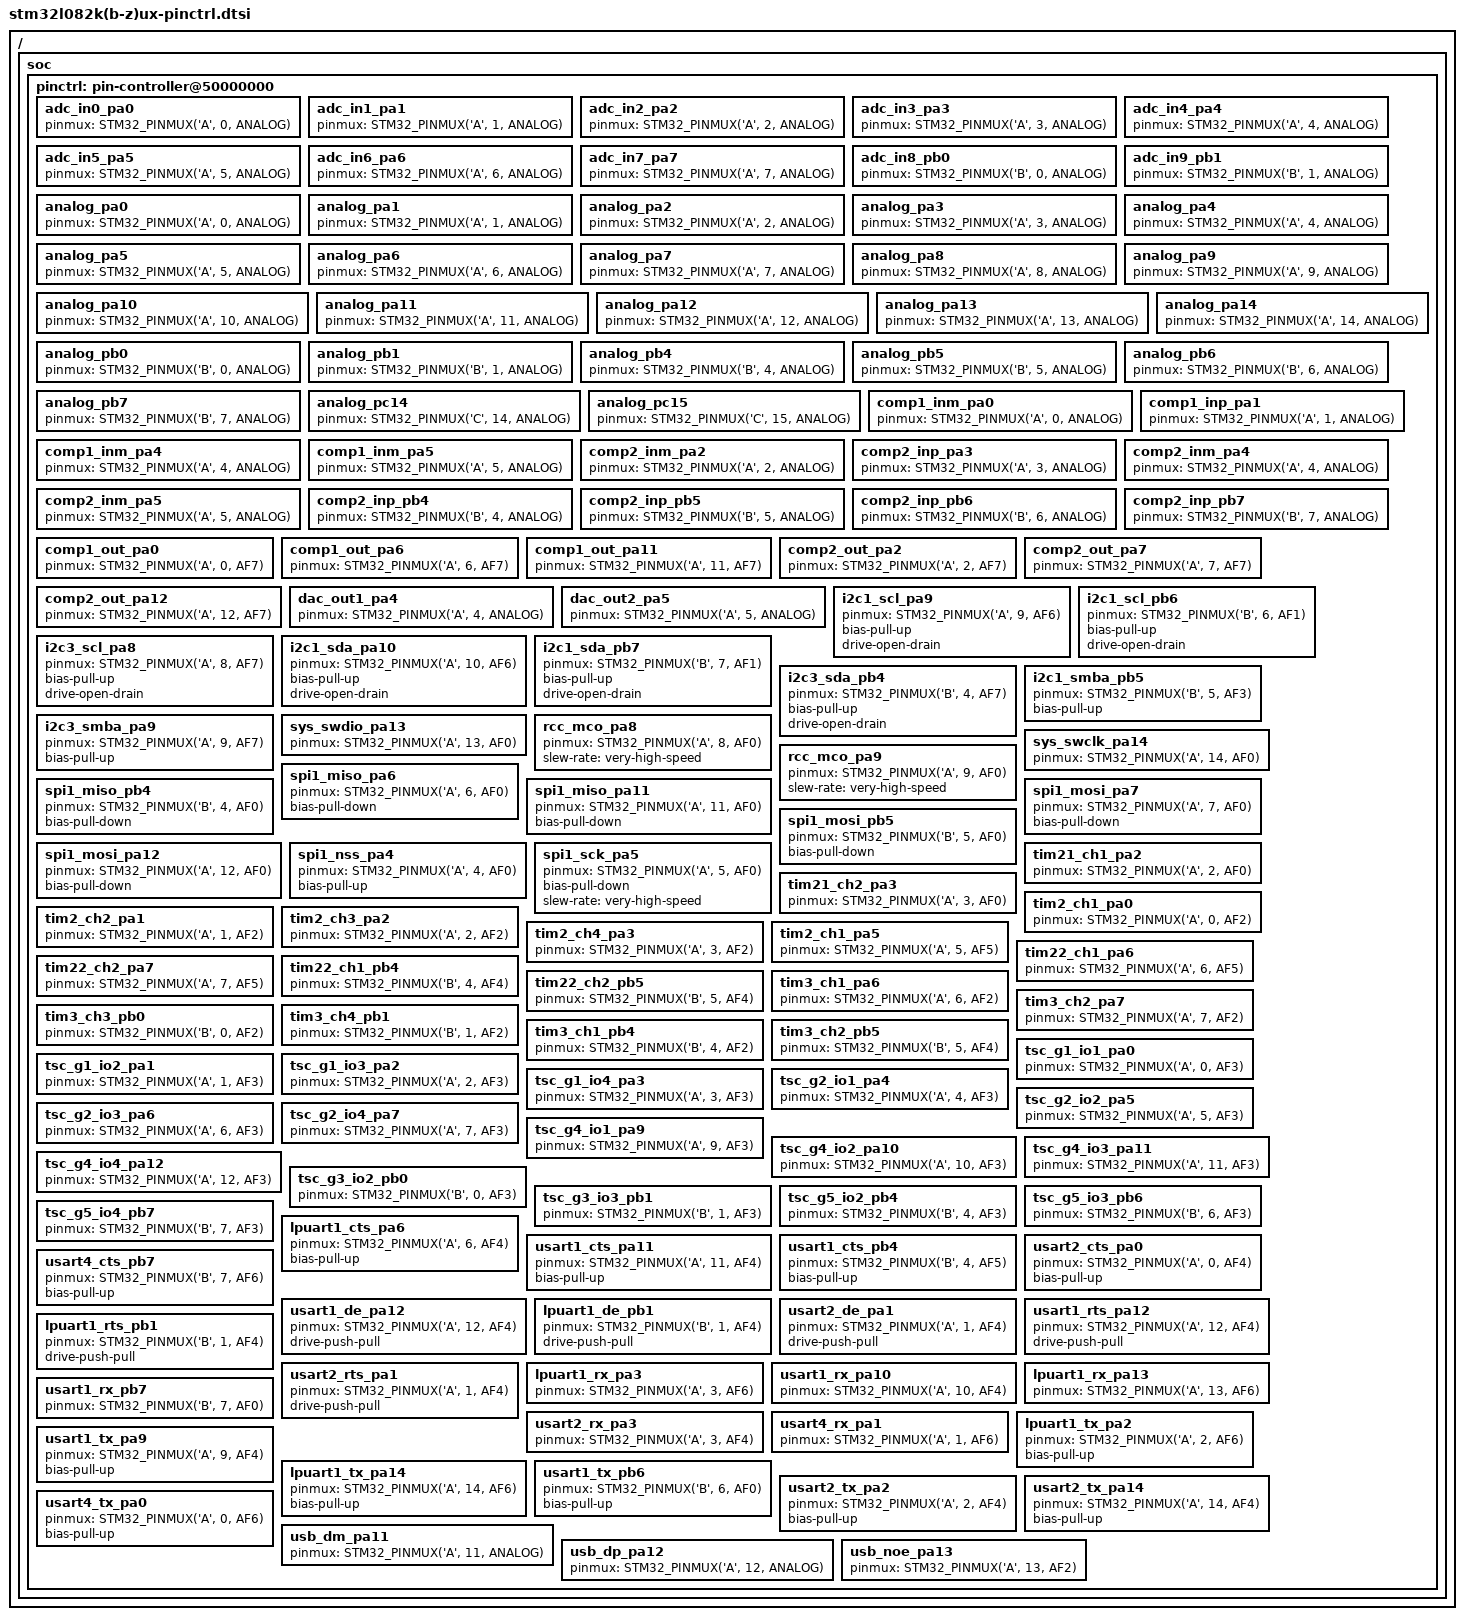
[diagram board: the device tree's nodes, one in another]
/*
 * NOTE: Autogenerated file using genpinctrl.py
 *
 * SPDX-License-Identifier: Apache-2.0
 */

#include <zephyr/dt-bindings/pinctrl/stm32-pinctrl.h>

/ {
	soc {
		pinctrl: pin-controller@50000000 {

			/* ADC_IN / ADC_INN / ADC_INP */

			/omit-if-no-ref/ adc_in0_pa0: adc_in0_pa0 {
				pinmux = <STM32_PINMUX('A', 0, ANALOG)>;
			};

			/omit-if-no-ref/ adc_in1_pa1: adc_in1_pa1 {
				pinmux = <STM32_PINMUX('A', 1, ANALOG)>;
			};

			/omit-if-no-ref/ adc_in2_pa2: adc_in2_pa2 {
				pinmux = <STM32_PINMUX('A', 2, ANALOG)>;
			};

			/omit-if-no-ref/ adc_in3_pa3: adc_in3_pa3 {
				pinmux = <STM32_PINMUX('A', 3, ANALOG)>;
			};

			/omit-if-no-ref/ adc_in4_pa4: adc_in4_pa4 {
				pinmux = <STM32_PINMUX('A', 4, ANALOG)>;
			};

			/omit-if-no-ref/ adc_in5_pa5: adc_in5_pa5 {
				pinmux = <STM32_PINMUX('A', 5, ANALOG)>;
			};

			/omit-if-no-ref/ adc_in6_pa6: adc_in6_pa6 {
				pinmux = <STM32_PINMUX('A', 6, ANALOG)>;
			};

			/omit-if-no-ref/ adc_in7_pa7: adc_in7_pa7 {
				pinmux = <STM32_PINMUX('A', 7, ANALOG)>;
			};

			/omit-if-no-ref/ adc_in8_pb0: adc_in8_pb0 {
				pinmux = <STM32_PINMUX('B', 0, ANALOG)>;
			};

			/omit-if-no-ref/ adc_in9_pb1: adc_in9_pb1 {
				pinmux = <STM32_PINMUX('B', 1, ANALOG)>;
			};

			/* Analog */

			/omit-if-no-ref/ analog_pa0: analog_pa0 {
				pinmux = <STM32_PINMUX('A', 0, ANALOG)>;
			};

			/omit-if-no-ref/ analog_pa1: analog_pa1 {
				pinmux = <STM32_PINMUX('A', 1, ANALOG)>;
			};

			/omit-if-no-ref/ analog_pa2: analog_pa2 {
				pinmux = <STM32_PINMUX('A', 2, ANALOG)>;
			};

			/omit-if-no-ref/ analog_pa3: analog_pa3 {
				pinmux = <STM32_PINMUX('A', 3, ANALOG)>;
			};

			/omit-if-no-ref/ analog_pa4: analog_pa4 {
				pinmux = <STM32_PINMUX('A', 4, ANALOG)>;
			};

			/omit-if-no-ref/ analog_pa5: analog_pa5 {
				pinmux = <STM32_PINMUX('A', 5, ANALOG)>;
			};

			/omit-if-no-ref/ analog_pa6: analog_pa6 {
				pinmux = <STM32_PINMUX('A', 6, ANALOG)>;
			};

			/omit-if-no-ref/ analog_pa7: analog_pa7 {
				pinmux = <STM32_PINMUX('A', 7, ANALOG)>;
			};

			/omit-if-no-ref/ analog_pa8: analog_pa8 {
				pinmux = <STM32_PINMUX('A', 8, ANALOG)>;
			};

			/omit-if-no-ref/ analog_pa9: analog_pa9 {
				pinmux = <STM32_PINMUX('A', 9, ANALOG)>;
			};

			/omit-if-no-ref/ analog_pa10: analog_pa10 {
				pinmux = <STM32_PINMUX('A', 10, ANALOG)>;
			};

			/omit-if-no-ref/ analog_pa11: analog_pa11 {
				pinmux = <STM32_PINMUX('A', 11, ANALOG)>;
			};

			/omit-if-no-ref/ analog_pa12: analog_pa12 {
				pinmux = <STM32_PINMUX('A', 12, ANALOG)>;
			};

			/omit-if-no-ref/ analog_pa13: analog_pa13 {
				pinmux = <STM32_PINMUX('A', 13, ANALOG)>;
			};

			/omit-if-no-ref/ analog_pa14: analog_pa14 {
				pinmux = <STM32_PINMUX('A', 14, ANALOG)>;
			};

			/omit-if-no-ref/ analog_pb0: analog_pb0 {
				pinmux = <STM32_PINMUX('B', 0, ANALOG)>;
			};

			/omit-if-no-ref/ analog_pb1: analog_pb1 {
				pinmux = <STM32_PINMUX('B', 1, ANALOG)>;
			};

			/omit-if-no-ref/ analog_pb4: analog_pb4 {
				pinmux = <STM32_PINMUX('B', 4, ANALOG)>;
			};

			/omit-if-no-ref/ analog_pb5: analog_pb5 {
				pinmux = <STM32_PINMUX('B', 5, ANALOG)>;
			};

			/omit-if-no-ref/ analog_pb6: analog_pb6 {
				pinmux = <STM32_PINMUX('B', 6, ANALOG)>;
			};

			/omit-if-no-ref/ analog_pb7: analog_pb7 {
				pinmux = <STM32_PINMUX('B', 7, ANALOG)>;
			};

			/omit-if-no-ref/ analog_pc14: analog_pc14 {
				pinmux = <STM32_PINMUX('C', 14, ANALOG)>;
			};

			/omit-if-no-ref/ analog_pc15: analog_pc15 {
				pinmux = <STM32_PINMUX('C', 15, ANALOG)>;
			};

			/* COMP_IN */

			/omit-if-no-ref/ comp1_inm_pa0: comp1_inm_pa0 {
				pinmux = <STM32_PINMUX('A', 0, ANALOG)>;
			};

			/omit-if-no-ref/ comp1_inp_pa1: comp1_inp_pa1 {
				pinmux = <STM32_PINMUX('A', 1, ANALOG)>;
			};

			/omit-if-no-ref/ comp1_inm_pa4: comp1_inm_pa4 {
				pinmux = <STM32_PINMUX('A', 4, ANALOG)>;
			};

			/omit-if-no-ref/ comp1_inm_pa5: comp1_inm_pa5 {
				pinmux = <STM32_PINMUX('A', 5, ANALOG)>;
			};

			/omit-if-no-ref/ comp2_inm_pa2: comp2_inm_pa2 {
				pinmux = <STM32_PINMUX('A', 2, ANALOG)>;
			};

			/omit-if-no-ref/ comp2_inp_pa3: comp2_inp_pa3 {
				pinmux = <STM32_PINMUX('A', 3, ANALOG)>;
			};

			/omit-if-no-ref/ comp2_inm_pa4: comp2_inm_pa4 {
				pinmux = <STM32_PINMUX('A', 4, ANALOG)>;
			};

			/omit-if-no-ref/ comp2_inm_pa5: comp2_inm_pa5 {
				pinmux = <STM32_PINMUX('A', 5, ANALOG)>;
			};

			/omit-if-no-ref/ comp2_inp_pb4: comp2_inp_pb4 {
				pinmux = <STM32_PINMUX('B', 4, ANALOG)>;
			};

			/omit-if-no-ref/ comp2_inp_pb5: comp2_inp_pb5 {
				pinmux = <STM32_PINMUX('B', 5, ANALOG)>;
			};

			/omit-if-no-ref/ comp2_inp_pb6: comp2_inp_pb6 {
				pinmux = <STM32_PINMUX('B', 6, ANALOG)>;
			};

			/omit-if-no-ref/ comp2_inp_pb7: comp2_inp_pb7 {
				pinmux = <STM32_PINMUX('B', 7, ANALOG)>;
			};

			/* COMP_OUT */

			/omit-if-no-ref/ comp1_out_pa0: comp1_out_pa0 {
				pinmux = <STM32_PINMUX('A', 0, AF7)>;
			};

			/omit-if-no-ref/ comp1_out_pa6: comp1_out_pa6 {
				pinmux = <STM32_PINMUX('A', 6, AF7)>;
			};

			/omit-if-no-ref/ comp1_out_pa11: comp1_out_pa11 {
				pinmux = <STM32_PINMUX('A', 11, AF7)>;
			};

			/omit-if-no-ref/ comp2_out_pa2: comp2_out_pa2 {
				pinmux = <STM32_PINMUX('A', 2, AF7)>;
			};

			/omit-if-no-ref/ comp2_out_pa7: comp2_out_pa7 {
				pinmux = <STM32_PINMUX('A', 7, AF7)>;
			};

			/omit-if-no-ref/ comp2_out_pa12: comp2_out_pa12 {
				pinmux = <STM32_PINMUX('A', 12, AF7)>;
			};

			/* DAC_OUT */

			/omit-if-no-ref/ dac_out1_pa4: dac_out1_pa4 {
				pinmux = <STM32_PINMUX('A', 4, ANALOG)>;
			};

			/omit-if-no-ref/ dac_out2_pa5: dac_out2_pa5 {
				pinmux = <STM32_PINMUX('A', 5, ANALOG)>;
			};

			/* I2C_SCL */

			/omit-if-no-ref/ i2c1_scl_pa9: i2c1_scl_pa9 {
				pinmux = <STM32_PINMUX('A', 9, AF6)>;
				bias-pull-up;
				drive-open-drain;
			};

			/omit-if-no-ref/ i2c1_scl_pb6: i2c1_scl_pb6 {
				pinmux = <STM32_PINMUX('B', 6, AF1)>;
				bias-pull-up;
				drive-open-drain;
			};

			/omit-if-no-ref/ i2c3_scl_pa8: i2c3_scl_pa8 {
				pinmux = <STM32_PINMUX('A', 8, AF7)>;
				bias-pull-up;
				drive-open-drain;
			};

			/* I2C_SDA */

			/omit-if-no-ref/ i2c1_sda_pa10: i2c1_sda_pa10 {
				pinmux = <STM32_PINMUX('A', 10, AF6)>;
				bias-pull-up;
				drive-open-drain;
			};

			/omit-if-no-ref/ i2c1_sda_pb7: i2c1_sda_pb7 {
				pinmux = <STM32_PINMUX('B', 7, AF1)>;
				bias-pull-up;
				drive-open-drain;
			};

			/omit-if-no-ref/ i2c3_sda_pb4: i2c3_sda_pb4 {
				pinmux = <STM32_PINMUX('B', 4, AF7)>;
				bias-pull-up;
				drive-open-drain;
			};

			/* I2C_SMBA */

			/omit-if-no-ref/ i2c1_smba_pb5: i2c1_smba_pb5 {
				pinmux = <STM32_PINMUX('B', 5, AF3)>;
				bias-pull-up;
			};

			/omit-if-no-ref/ i2c3_smba_pa9: i2c3_smba_pa9 {
				pinmux = <STM32_PINMUX('A', 9, AF7)>;
				bias-pull-up;
			};

			/* JTAG PORT */

			/omit-if-no-ref/ sys_swdio_pa13: sys_swdio_pa13 {
				pinmux = <STM32_PINMUX('A', 13, AF0)>;
			};

			/omit-if-no-ref/ sys_swclk_pa14: sys_swclk_pa14 {
				pinmux = <STM32_PINMUX('A', 14, AF0)>;
			};

			/* RCC_MCO */

			/omit-if-no-ref/ rcc_mco_pa8: rcc_mco_pa8 {
				pinmux = <STM32_PINMUX('A', 8, AF0)>;
				slew-rate = "very-high-speed";
			};

			/omit-if-no-ref/ rcc_mco_pa9: rcc_mco_pa9 {
				pinmux = <STM32_PINMUX('A', 9, AF0)>;
				slew-rate = "very-high-speed";
			};

			/* SPI_MISO */

			/omit-if-no-ref/ spi1_miso_pa6: spi1_miso_pa6 {
				pinmux = <STM32_PINMUX('A', 6, AF0)>;
				bias-pull-down;
			};

			/omit-if-no-ref/ spi1_miso_pa11: spi1_miso_pa11 {
				pinmux = <STM32_PINMUX('A', 11, AF0)>;
				bias-pull-down;
			};

			/omit-if-no-ref/ spi1_miso_pb4: spi1_miso_pb4 {
				pinmux = <STM32_PINMUX('B', 4, AF0)>;
				bias-pull-down;
			};

			/* SPI_MOSI */

			/omit-if-no-ref/ spi1_mosi_pa7: spi1_mosi_pa7 {
				pinmux = <STM32_PINMUX('A', 7, AF0)>;
				bias-pull-down;
			};

			/omit-if-no-ref/ spi1_mosi_pa12: spi1_mosi_pa12 {
				pinmux = <STM32_PINMUX('A', 12, AF0)>;
				bias-pull-down;
			};

			/omit-if-no-ref/ spi1_mosi_pb5: spi1_mosi_pb5 {
				pinmux = <STM32_PINMUX('B', 5, AF0)>;
				bias-pull-down;
			};

			/* SPI_NSS */

			/omit-if-no-ref/ spi1_nss_pa4: spi1_nss_pa4 {
				pinmux = <STM32_PINMUX('A', 4, AF0)>;
				bias-pull-up;
			};

			/* SPI_SCK */

			/omit-if-no-ref/ spi1_sck_pa5: spi1_sck_pa5 {
				pinmux = <STM32_PINMUX('A', 5, AF0)>;
				bias-pull-down;
				slew-rate = "very-high-speed";
			};

			/* TIM_CH / TIM_CHN */

			/omit-if-no-ref/ tim21_ch1_pa2: tim21_ch1_pa2 {
				pinmux = <STM32_PINMUX('A', 2, AF0)>;
			};

			/omit-if-no-ref/ tim21_ch2_pa3: tim21_ch2_pa3 {
				pinmux = <STM32_PINMUX('A', 3, AF0)>;
			};

			/omit-if-no-ref/ tim2_ch1_pa0: tim2_ch1_pa0 {
				pinmux = <STM32_PINMUX('A', 0, AF2)>;
			};

			/omit-if-no-ref/ tim2_ch2_pa1: tim2_ch2_pa1 {
				pinmux = <STM32_PINMUX('A', 1, AF2)>;
			};

			/omit-if-no-ref/ tim2_ch3_pa2: tim2_ch3_pa2 {
				pinmux = <STM32_PINMUX('A', 2, AF2)>;
			};

			/omit-if-no-ref/ tim2_ch4_pa3: tim2_ch4_pa3 {
				pinmux = <STM32_PINMUX('A', 3, AF2)>;
			};

			/omit-if-no-ref/ tim2_ch1_pa5: tim2_ch1_pa5 {
				pinmux = <STM32_PINMUX('A', 5, AF5)>;
			};

			/omit-if-no-ref/ tim22_ch1_pa6: tim22_ch1_pa6 {
				pinmux = <STM32_PINMUX('A', 6, AF5)>;
			};

			/omit-if-no-ref/ tim22_ch2_pa7: tim22_ch2_pa7 {
				pinmux = <STM32_PINMUX('A', 7, AF5)>;
			};

			/omit-if-no-ref/ tim22_ch1_pb4: tim22_ch1_pb4 {
				pinmux = <STM32_PINMUX('B', 4, AF4)>;
			};

			/omit-if-no-ref/ tim22_ch2_pb5: tim22_ch2_pb5 {
				pinmux = <STM32_PINMUX('B', 5, AF4)>;
			};

			/omit-if-no-ref/ tim3_ch1_pa6: tim3_ch1_pa6 {
				pinmux = <STM32_PINMUX('A', 6, AF2)>;
			};

			/omit-if-no-ref/ tim3_ch2_pa7: tim3_ch2_pa7 {
				pinmux = <STM32_PINMUX('A', 7, AF2)>;
			};

			/omit-if-no-ref/ tim3_ch3_pb0: tim3_ch3_pb0 {
				pinmux = <STM32_PINMUX('B', 0, AF2)>;
			};

			/omit-if-no-ref/ tim3_ch4_pb1: tim3_ch4_pb1 {
				pinmux = <STM32_PINMUX('B', 1, AF2)>;
			};

			/omit-if-no-ref/ tim3_ch1_pb4: tim3_ch1_pb4 {
				pinmux = <STM32_PINMUX('B', 4, AF2)>;
			};

			/omit-if-no-ref/ tim3_ch2_pb5: tim3_ch2_pb5 {
				pinmux = <STM32_PINMUX('B', 5, AF4)>;
			};

			/* TSC */

			/omit-if-no-ref/ tsc_g1_io1_pa0: tsc_g1_io1_pa0 {
				pinmux = <STM32_PINMUX('A', 0, AF3)>;
			};

			/omit-if-no-ref/ tsc_g1_io2_pa1: tsc_g1_io2_pa1 {
				pinmux = <STM32_PINMUX('A', 1, AF3)>;
			};

			/omit-if-no-ref/ tsc_g1_io3_pa2: tsc_g1_io3_pa2 {
				pinmux = <STM32_PINMUX('A', 2, AF3)>;
			};

			/omit-if-no-ref/ tsc_g1_io4_pa3: tsc_g1_io4_pa3 {
				pinmux = <STM32_PINMUX('A', 3, AF3)>;
			};

			/omit-if-no-ref/ tsc_g2_io1_pa4: tsc_g2_io1_pa4 {
				pinmux = <STM32_PINMUX('A', 4, AF3)>;
			};

			/omit-if-no-ref/ tsc_g2_io2_pa5: tsc_g2_io2_pa5 {
				pinmux = <STM32_PINMUX('A', 5, AF3)>;
			};

			/omit-if-no-ref/ tsc_g2_io3_pa6: tsc_g2_io3_pa6 {
				pinmux = <STM32_PINMUX('A', 6, AF3)>;
			};

			/omit-if-no-ref/ tsc_g2_io4_pa7: tsc_g2_io4_pa7 {
				pinmux = <STM32_PINMUX('A', 7, AF3)>;
			};

			/omit-if-no-ref/ tsc_g4_io1_pa9: tsc_g4_io1_pa9 {
				pinmux = <STM32_PINMUX('A', 9, AF3)>;
			};

			/omit-if-no-ref/ tsc_g4_io2_pa10: tsc_g4_io2_pa10 {
				pinmux = <STM32_PINMUX('A', 10, AF3)>;
			};

			/omit-if-no-ref/ tsc_g4_io3_pa11: tsc_g4_io3_pa11 {
				pinmux = <STM32_PINMUX('A', 11, AF3)>;
			};

			/omit-if-no-ref/ tsc_g4_io4_pa12: tsc_g4_io4_pa12 {
				pinmux = <STM32_PINMUX('A', 12, AF3)>;
			};

			/omit-if-no-ref/ tsc_g3_io2_pb0: tsc_g3_io2_pb0 {
				pinmux = <STM32_PINMUX('B', 0, AF3)>;
			};

			/omit-if-no-ref/ tsc_g3_io3_pb1: tsc_g3_io3_pb1 {
				pinmux = <STM32_PINMUX('B', 1, AF3)>;
			};

			/omit-if-no-ref/ tsc_g5_io2_pb4: tsc_g5_io2_pb4 {
				pinmux = <STM32_PINMUX('B', 4, AF3)>;
			};

			/omit-if-no-ref/ tsc_g5_io3_pb6: tsc_g5_io3_pb6 {
				pinmux = <STM32_PINMUX('B', 6, AF3)>;
			};

			/omit-if-no-ref/ tsc_g5_io4_pb7: tsc_g5_io4_pb7 {
				pinmux = <STM32_PINMUX('B', 7, AF3)>;
			};

			/* UART_CTS / USART_CTS / LPUART_CTS */

			/omit-if-no-ref/ lpuart1_cts_pa6: lpuart1_cts_pa6 {
				pinmux = <STM32_PINMUX('A', 6, AF4)>;
				bias-pull-up;
			};

			/omit-if-no-ref/ usart1_cts_pa11: usart1_cts_pa11 {
				pinmux = <STM32_PINMUX('A', 11, AF4)>;
				bias-pull-up;
			};

			/omit-if-no-ref/ usart1_cts_pb4: usart1_cts_pb4 {
				pinmux = <STM32_PINMUX('B', 4, AF5)>;
				bias-pull-up;
			};

			/omit-if-no-ref/ usart2_cts_pa0: usart2_cts_pa0 {
				pinmux = <STM32_PINMUX('A', 0, AF4)>;
				bias-pull-up;
			};

			/omit-if-no-ref/ usart4_cts_pb7: usart4_cts_pb7 {
				pinmux = <STM32_PINMUX('B', 7, AF6)>;
				bias-pull-up;
			};

			/* UART_DE / USART_DE / LPUART_DE */

			/omit-if-no-ref/ usart1_de_pa12: usart1_de_pa12 {
				pinmux = <STM32_PINMUX('A', 12, AF4)>;
				drive-push-pull;
			};

			/omit-if-no-ref/ lpuart1_de_pb1: lpuart1_de_pb1 {
				pinmux = <STM32_PINMUX('B', 1, AF4)>;
				drive-push-pull;
			};

			/omit-if-no-ref/ usart2_de_pa1: usart2_de_pa1 {
				pinmux = <STM32_PINMUX('A', 1, AF4)>;
				drive-push-pull;
			};

			/* UART_RTS / USART_RTS / LPUART_RTS */

			/omit-if-no-ref/ usart1_rts_pa12: usart1_rts_pa12 {
				pinmux = <STM32_PINMUX('A', 12, AF4)>;
				drive-push-pull;
			};

			/omit-if-no-ref/ lpuart1_rts_pb1: lpuart1_rts_pb1 {
				pinmux = <STM32_PINMUX('B', 1, AF4)>;
				drive-push-pull;
			};

			/omit-if-no-ref/ usart2_rts_pa1: usart2_rts_pa1 {
				pinmux = <STM32_PINMUX('A', 1, AF4)>;
				drive-push-pull;
			};

			/* UART_RX / USART_RX / LPUART_RX */

			/omit-if-no-ref/ lpuart1_rx_pa3: lpuart1_rx_pa3 {
				pinmux = <STM32_PINMUX('A', 3, AF6)>;
			};

			/omit-if-no-ref/ usart1_rx_pa10: usart1_rx_pa10 {
				pinmux = <STM32_PINMUX('A', 10, AF4)>;
			};

			/omit-if-no-ref/ lpuart1_rx_pa13: lpuart1_rx_pa13 {
				pinmux = <STM32_PINMUX('A', 13, AF6)>;
			};

			/omit-if-no-ref/ usart1_rx_pb7: usart1_rx_pb7 {
				pinmux = <STM32_PINMUX('B', 7, AF0)>;
			};

			/omit-if-no-ref/ usart2_rx_pa3: usart2_rx_pa3 {
				pinmux = <STM32_PINMUX('A', 3, AF4)>;
			};

			/omit-if-no-ref/ usart4_rx_pa1: usart4_rx_pa1 {
				pinmux = <STM32_PINMUX('A', 1, AF6)>;
			};

			/* UART_TX / USART_TX / LPUART_TX */

			/omit-if-no-ref/ lpuart1_tx_pa2: lpuart1_tx_pa2 {
				pinmux = <STM32_PINMUX('A', 2, AF6)>;
				bias-pull-up;
			};

			/omit-if-no-ref/ usart1_tx_pa9: usart1_tx_pa9 {
				pinmux = <STM32_PINMUX('A', 9, AF4)>;
				bias-pull-up;
			};

			/omit-if-no-ref/ lpuart1_tx_pa14: lpuart1_tx_pa14 {
				pinmux = <STM32_PINMUX('A', 14, AF6)>;
				bias-pull-up;
			};

			/omit-if-no-ref/ usart1_tx_pb6: usart1_tx_pb6 {
				pinmux = <STM32_PINMUX('B', 6, AF0)>;
				bias-pull-up;
			};

			/omit-if-no-ref/ usart2_tx_pa2: usart2_tx_pa2 {
				pinmux = <STM32_PINMUX('A', 2, AF4)>;
				bias-pull-up;
			};

			/omit-if-no-ref/ usart2_tx_pa14: usart2_tx_pa14 {
				pinmux = <STM32_PINMUX('A', 14, AF4)>;
				bias-pull-up;
			};

			/omit-if-no-ref/ usart4_tx_pa0: usart4_tx_pa0 {
				pinmux = <STM32_PINMUX('A', 0, AF6)>;
				bias-pull-up;
			};

			/* USB */

			/omit-if-no-ref/ usb_dm_pa11: usb_dm_pa11 {
				pinmux = <STM32_PINMUX('A', 11, ANALOG)>;
			};

			/omit-if-no-ref/ usb_dp_pa12: usb_dp_pa12 {
				pinmux = <STM32_PINMUX('A', 12, ANALOG)>;
			};

			/omit-if-no-ref/ usb_noe_pa13: usb_noe_pa13 {
				pinmux = <STM32_PINMUX('A', 13, AF2)>;
			};

		};
	};
};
